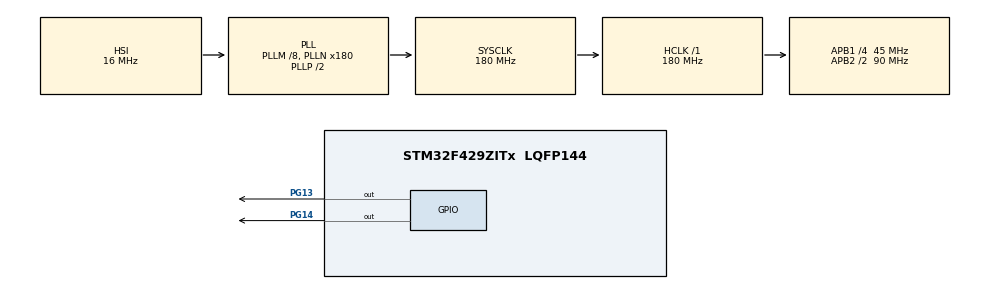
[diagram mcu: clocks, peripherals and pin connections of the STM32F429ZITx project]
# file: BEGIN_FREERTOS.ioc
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Mcu.Family=STM32F4
Mcu.Name=STM32F429ZITx
Mcu.Package=LQFP144
NVIC.PriorityGroup=NVIC_PRIORITYGROUP_4
PA13.Mode=Serial_Wire
PA13.Signal=SYS_JTMS-SWDIO
PA14.Mode=Serial_Wire
PA14.Signal=SYS_JTCK-SWCLK
PG13.Signal=GPIO_Output
PG14.Signal=GPIO_Output
ProjectManager.HeapSize=0x200
ProjectManager.StackSize=0x400
ProjectManager.TargetToolchain=STM32CubeIDE
RCC.48MHZClocksFreq_Value=90000000
RCC.AHBFreq_Value=180000000
RCC.APB1CLKDivider=RCC_HCLK_DIV4
RCC.APB1Freq_Value=45000000
RCC.APB1TimFreq_Value=90000000
RCC.APB2CLKDivider=RCC_HCLK_DIV2
RCC.APB2Freq_Value=90000000
RCC.APB2TimFreq_Value=180000000
RCC.CortexFreq_Value=180000000
RCC.HCLKFreq_Value=180000000
RCC.HSE_VALUE=25000000
RCC.HSI_VALUE=16000000
RCC.LSE_VALUE=32768
RCC.PLLM=8
RCC.PLLN=180
RCC.SYSCLKFreq_VALUE=180000000
RCC.SYSCLKSource=RCC_SYSCLKSOURCE_PLLCLK
RCC.VCOOutputFreq_Value=360000000
board=custom

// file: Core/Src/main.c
/* USER CODE BEGIN Header */
/**
  ******************************************************************************
  * @file           : main.c
  * @brief          : Main program body
  ******************************************************************************
  * @attention
  *
  * Copyright (c) 2024 STMicroelectronics.
  * All rights reserved.
  *
  * This software is licensed under terms that can be found in the LICENSE file
  * in the root directory of this software component.
  * If no LICENSE file comes with this software, it is provided AS-IS.
  *
  ******************************************************************************
  */
/* USER CODE END Header */
#include "main.h"

/* USER CODE BEGIN Includes */
#include "stdio.h"
#include "FreeRTOS.h"
#include "task.h"
/* USER CODE END Includes */

void SystemClock_Config(void);
static void MX_GPIO_Init(void);
/* USER CODE BEGIN PFP */
static void TASK1 (void* parameters);
static void TASK2 (void* parameters);
/* USER CODE END PFP */

int main(void)
{

  /* USER CODE BEGIN 1 */
	TaskHandle_t T1;
	TaskHandle_t T2;
	BaseType_t stt1;
	BaseType_t stt2;
  /* USER CODE END 1 */

  /* MCU Configuration--------------------------------------------------------*/

  /* Reset of all peripherals, Initializes the Flash interface and the Systick. */
  HAL_Init();

  /* Configure the system clock */
  SystemClock_Config();

  /* Initialize all configured peripherals */
  MX_GPIO_Init();
  /* USER CODE BEGIN 2 */
  stt1 = xTaskCreate(TASK1,"Task1",200,"Hello World From Task 1",2,&T1);
  configASSERT(stt1 = pdPASS);
  stt2 = xTaskCreate(TASK2,"Task2",200,"Hello World From Task 2",2,&T2);
  configASSERT(stt2 = pdPASS);
  vTaskStartScheduler();

  /* USER CODE END 2 */

  /* Infinite loop */
  while (1)
  {

  }
}

void SystemClock_Config(void)
{
  RCC_OscInitTypeDef RCC_OscInitStruct = {0};
  RCC_ClkInitTypeDef RCC_ClkInitStruct = {0};

  /** Configure the main internal regulator output voltage
  */
  __HAL_RCC_PWR_CLK_ENABLE();
  __HAL_PWR_VOLTAGESCALING_CONFIG(PWR_REGULATOR_VOLTAGE_SCALE1);

  /** Initializes the RCC Oscillators according to the specified parameters
  * in the RCC_OscInitTypeDef structure.
  */
  RCC_OscInitStruct.OscillatorType = RCC_OSCILLATORTYPE_HSI;
  RCC_OscInitStruct.HSIState = RCC_HSI_ON;
  RCC_OscInitStruct.HSICalibrationValue = RCC_HSICALIBRATION_DEFAULT;
  RCC_OscInitStruct.PLL.PLLState = RCC_PLL_ON;
  RCC_OscInitStruct.PLL.PLLSource = RCC_PLLSOURCE_HSI;
  RCC_OscInitStruct.PLL.PLLM = 8;
  RCC_OscInitStruct.PLL.PLLN = 180;
  RCC_OscInitStruct.PLL.PLLP = RCC_PLLP_DIV2;
  RCC_OscInitStruct.PLL.PLLQ = 4;
  if (HAL_RCC_OscConfig(&RCC_OscInitStruct) != HAL_OK)
  {
    Error_Handler();
  }

  /** Activate the Over-Drive mode
  */
  if (HAL_PWREx_EnableOverDrive() != HAL_OK)
  {
    Error_Handler();
  }

  /** Initializes the CPU, AHB and APB buses clocks
  */
  RCC_ClkInitStruct.ClockType = RCC_CLOCKTYPE_HCLK|RCC_CLOCKTYPE_SYSCLK
                              |RCC_CLOCKTYPE_PCLK1|RCC_CLOCKTYPE_PCLK2;
  RCC_ClkInitStruct.SYSCLKSource = RCC_SYSCLKSOURCE_PLLCLK;
  RCC_ClkInitStruct.AHBCLKDivider = RCC_SYSCLK_DIV1;
  RCC_ClkInitStruct.APB1CLKDivider = RCC_HCLK_DIV4;
  RCC_ClkInitStruct.APB2CLKDivider = RCC_HCLK_DIV2;

  if (HAL_RCC_ClockConfig(&RCC_ClkInitStruct, FLASH_LATENCY_5) != HAL_OK)
  {
    Error_Handler();
  }
}

static void MX_GPIO_Init(void)
{
  GPIO_InitTypeDef GPIO_InitStruct = {0};

  /* GPIO Ports Clock Enable */
  __HAL_RCC_GPIOA_CLK_ENABLE();
  __HAL_RCC_GPIOG_CLK_ENABLE();

  /*Configure GPIO pin Output Level */
  HAL_GPIO_WritePin(GPIOG, GPIO_PIN_13|GPIO_PIN_14, GPIO_PIN_RESET);

  /*Configure GPIO pins : PG13 PG14 */
  GPIO_InitStruct.Pin = GPIO_PIN_13|GPIO_PIN_14;
  GPIO_InitStruct.Mode = GPIO_MODE_OUTPUT_PP;
  GPIO_InitStruct.Pull = GPIO_NOPULL;
  GPIO_InitStruct.Speed = GPIO_SPEED_FREQ_LOW;
  HAL_GPIO_Init(GPIOG, &GPIO_InitStruct);

}

/* USER CODE BEGIN 4 */
static void TASK1 (void* parameters)
{
	while(1)

		{

			printf("%s\n",(char*)parameters);

			taskYIELD();

		}
}
static void TASK2 (void* parameters)
{
	while(1)

		{

			printf("%s\n",(char*)parameters);

			taskYIELD();

		}
}

/* USER CODE END 4 */

void Error_Handler(void)
{
  __disable_irq();
  while (1)
  {
  }
}
